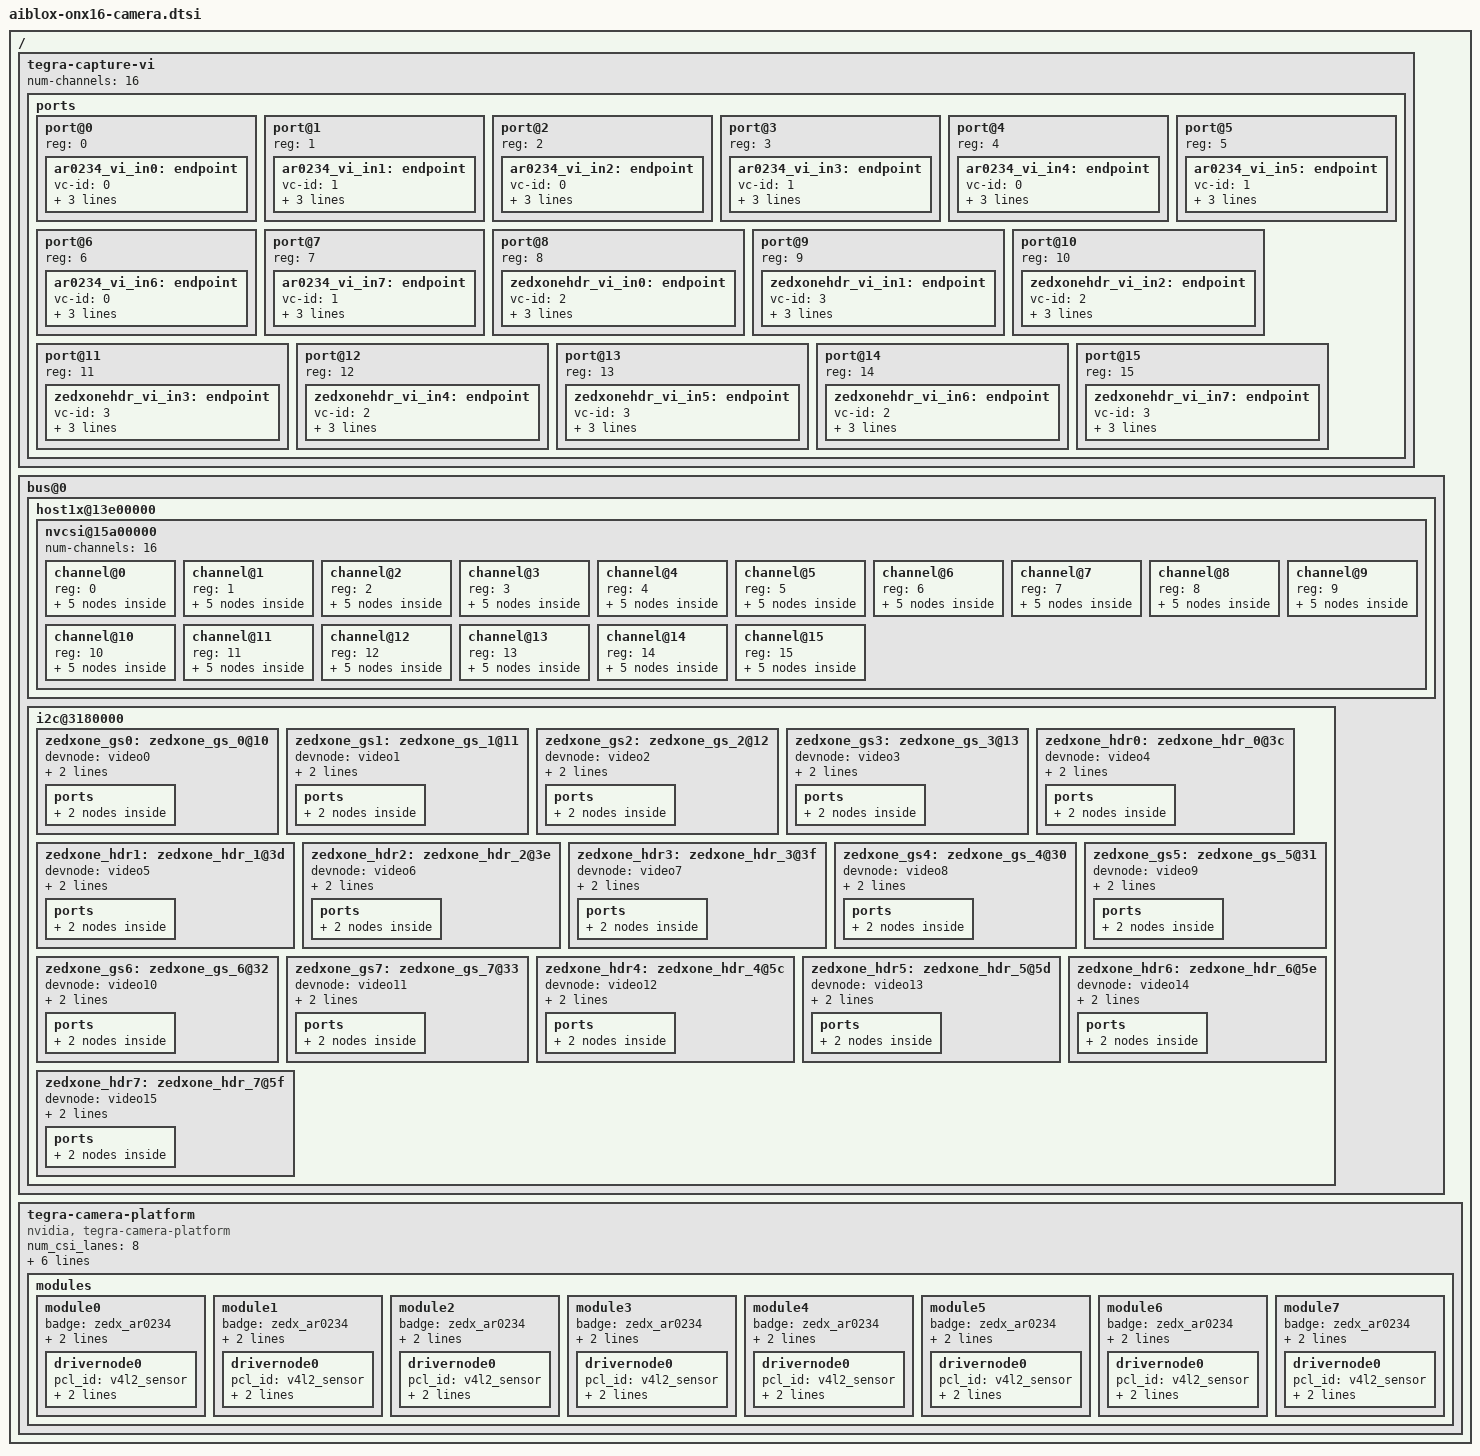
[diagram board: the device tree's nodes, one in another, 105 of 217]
// SPDX-License-Identifier: GPL-2.0-only
// SPDX-FileCopyrightText: Copyright (c) 2023-2024, NVIDIA CORPORATION & AFFILIATES. All rights reserved.

#include "Utils/isx031-sl-modes.dtsi"
#include "Utils/ar0234-sl-modes.dtsi"
#include "Utils/imx678-sl-modes.dtsi"

#define NUM_LANES 2

/ {
	fragment-camera-zedx-aiblox@0 {
		target-path = "/";
		__overlay__ {
			tegra-capture-vi {
				num-channels = <16>;
				ports {
					#address-cells = <1>;
					#size-cells = <0>;
					port@0 {
						reg = <0>;
						status = "okay";
						ar0234_vi_in0: endpoint {
							status = "okay";
							vc-id = <0>;
							port-index = <0>;
							bus-width = <NUM_LANES>;
							remote-endpoint = <&ar0234_csi_out0>;
						};
					};
					port@1 {
						reg = <1>;
						status = "okay";
						ar0234_vi_in1: endpoint {
							status = "okay";
							vc-id = <1>;
							port-index = <0>;
							bus-width = <NUM_LANES>;
							remote-endpoint = <&ar0234_csi_out1>;
						};
					};
					port@2 {
						reg = <2>;
						status = "okay";
						ar0234_vi_in2: endpoint {
							status = "okay";
							vc-id = <0>;
							port-index = <1>;
							bus-width = <NUM_LANES>;
							remote-endpoint = <&ar0234_csi_out2>;
						};
					};
					port@3 {
						reg = <3>;
						status = "okay";
						ar0234_vi_in3: endpoint {
							status = "okay";
							vc-id = <1>;
							port-index = <1>;
							bus-width = <NUM_LANES>;
							remote-endpoint = <&ar0234_csi_out3>;
						};
					};
					port@4 {
						reg = <4>;
						status = "okay";
						ar0234_vi_in4: endpoint {
							status = "okay";
							vc-id = <0>;
							port-index = <2>;
							bus-width = <NUM_LANES>;
							remote-endpoint = <&ar0234_csi_out4>;
						};
					};
					port@5 {
						reg = <5>;
						status = "okay";
						ar0234_vi_in5: endpoint {
							status = "okay";
							vc-id = <1>;
							port-index = <2>;
							bus-width = <NUM_LANES>;
							remote-endpoint = <&ar0234_csi_out5>;
						};
					};
					port@6 {
						reg = <6>;
						status = "okay";
						ar0234_vi_in6: endpoint {
							status = "okay";
							vc-id = <0>;
							port-index = <3>;
							bus-width = <NUM_LANES>;
							remote-endpoint = <&ar0234_csi_out6>;
						};
					};
					port@7 {
						reg = <7>;
						status = "okay";
						ar0234_vi_in7: endpoint {
							status = "okay";
							vc-id = <1>;
							port-index = <3>;
							bus-width = <NUM_LANES>;
							remote-endpoint = <&ar0234_csi_out7>;
						};
					};
					
					port@8 {
						reg = <8>;
						status = "okay";
						zedxonehdr_vi_in0: endpoint {
							status = "okay";
							vc-id = <2>;
							port-index = <0>;
							bus-width = <NUM_LANES>;
							remote-endpoint = <&zedxonehdr_csi_out0>;
						};
					};
					port@9 {
						reg = <9>;
						status = "okay";
						zedxonehdr_vi_in1: endpoint {
							status = "okay";
							vc-id = <3>;
							port-index = <0>;
							bus-width = <NUM_LANES>;
							remote-endpoint = <&zedxonehdr_csi_out1>;
						};
					};
					port@10 {
						reg = <10>;
						status = "okay";
						zedxonehdr_vi_in2: endpoint {
							status = "okay";
							vc-id = <2>;
							port-index = <1>;
							bus-width = <NUM_LANES>;
							remote-endpoint = <&zedxonehdr_csi_out2>;
						};
					};
					port@11 {
						reg = <11>;
						status = "okay";
						zedxonehdr_vi_in3: endpoint {
							status = "okay";
							vc-id = <3>;
							port-index = <1>;
							bus-width = <NUM_LANES>;
							remote-endpoint = <&zedxonehdr_csi_out3>;
						};
					};
					port@12 {
						reg = <12>;
						status = "okay";
						zedxonehdr_vi_in4: endpoint {
							status = "okay";
							vc-id = <2>;
							port-index = <2>;
							bus-width = <NUM_LANES>;
							remote-endpoint = <&zedxonehdr_csi_out4>;
						};
					};
					port@13 {
						reg = <13>;
						status = "okay";
						zedxonehdr_vi_in5: endpoint {
							status = "okay";
							vc-id = <3>;
							port-index = <2>;
							bus-width = <NUM_LANES>;
							remote-endpoint = <&zedxonehdr_csi_out5>;
						};
					};
					port@14 {
						reg = <14>;
						status = "okay";
						zedxonehdr_vi_in6: endpoint {
							status = "okay";
							vc-id = <2>;
							port-index = <3>;
							bus-width = <NUM_LANES>;
							remote-endpoint = <&zedxonehdr_csi_out6>;
						};
					};
					port@15 {
						reg = <15>;
						status = "okay";
						zedxonehdr_vi_in7: endpoint {
							status = "okay";
							vc-id = <3>;
							port-index = <3>;
							bus-width = <NUM_LANES>;
							remote-endpoint = <&zedxonehdr_csi_out7>;
						};
					};
				};
			};
			bus@0 {
				host1x@13e00000 {
					nvcsi@15a00000 {
						num-channels = <16>;
						#address-cells = <1>;
						#size-cells = <0>;
						channel@0 {
							reg = <0>;
							status = "okay";
							ports {
								#address-cells = <1>;
								#size-cells = <0>;
								port@0 {
									reg = <0>;
									status = "okay";
									ar0234_csi_in0: endpoint@0 {
										status = "okay";
										port-index = <0>;
										bus-width = <NUM_LANES>;
										remote-endpoint = <&ar0234_ar0234_out0>;
									};
								};
								port@1 {
									reg = <1>;
									status = "okay";
									ar0234_csi_out0: endpoint@1 {
										status = "okay";
										remote-endpoint = <&ar0234_vi_in0>;
									};
								};
							};
						};
						channel@1 {
							reg = <1>;
							status = "okay";
							ports {
								#address-cells = <1>;
								#size-cells = <0>;
								port@0 {
									reg = <0>;
									status = "okay";
									ar0234_csi_in1: endpoint@2 {
										status = "okay";
										port-index = <0>;
										bus-width = <NUM_LANES>;
										remote-endpoint = <&ar0234_ar0234_out1>;
									};
								};
								port@1 {
									reg = <1>;
									status = "okay";
									ar0234_csi_out1: endpoint@3 {
										status = "okay";
										remote-endpoint = <&ar0234_vi_in1>;
									};
								};
							};
						};
						channel@2 {
							reg = <2>;
							status = "okay";
							ports {
								#address-cells = <1>;
								#size-cells = <0>;
								port@0 {
									reg = <0>;
									status = "okay";
									ar0234_csi_in2: endpoint@4 {
										status = "okay";
										port-index = <1>;
										bus-width = <NUM_LANES>;
										remote-endpoint = <&ar0234_ar0234_out2>;
									};
								};
								port@1 {
									reg = <1>;
									status = "okay";
									ar0234_csi_out2: endpoint@5 {
										status = "okay";
										remote-endpoint = <&ar0234_vi_in2>;
									};
								};
							};
						};
						channel@3 {
							reg = <3>;
							status = "okay";
							ports {
								#address-cells = <1>;
								#size-cells = <0>;
								port@0 {
									reg = <0>;
									status = "okay";
									ar0234_csi_in3: endpoint@6 {
										status = "okay";
										port-index = <1>;
										bus-width = <NUM_LANES>;
										remote-endpoint = <&ar0234_ar0234_out3>;
									};
								};
								port@1 {
									reg = <1>;
									status = "okay";
									ar0234_csi_out3: endpoint@7 {
										status = "okay";
										remote-endpoint = <&ar0234_vi_in3>;
									};
								};
							};
						};
						channel@4 {
							reg = <4>;
							status = "okay";
							ports {
								#address-cells = <1>;
								#size-cells = <0>;
								port@0 {
									reg = <0>;
									status = "okay";
									ar0234_csi_in4: endpoint@8 {
										status = "okay";
										port-index = <2>;
										bus-width = <NUM_LANES>;
										remote-endpoint = <&ar0234_ar0234_out4>;
									};
								};
								port@1 {
									reg = <1>;
									status = "okay";
									ar0234_csi_out4: endpoint@9 {
										status = "okay";
										remote-endpoint = <&ar0234_vi_in4>;
									};
								};
							};
						};
						channel@5 {
							reg = <5>;
							status = "okay";
							ports {
								#address-cells = <1>;
								#size-cells = <0>;
								port@0 {
									reg = <0>;
									status = "okay";
									ar0234_csi_in5: endpoint@10 {
										status = "okay";
										port-index = <2>;
										bus-width = <NUM_LANES>;
										remote-endpoint = <&ar0234_ar0234_out5>;
									};
								};
								port@1 {
									reg = <1>;
									status = "okay";
									ar0234_csi_out5: endpoint@11 {
										status = "okay";
										remote-endpoint = <&ar0234_vi_in5>;
									};
								};
							};
						};
						channel@6 {
							reg = <6>;
							status = "okay";
							ports {
								#address-cells = <1>;
								#size-cells = <0>;
								port@0 {
									reg = <0>;
									status = "okay";
									ar0234_csi_in6: endpoint@12 {
										status = "okay";
										port-index = <3>;
										bus-width = <NUM_LANES>;
										remote-endpoint = <&ar0234_ar0234_out6>;
									};
								};
								port@1 {
									reg = <1>;
									status = "okay";
									ar0234_csi_out6: endpoint@13 {
										status = "okay";
										remote-endpoint = <&ar0234_vi_in6>;
									};
								};
							};
						};
						channel@7 {
							reg = <7>;
							status = "okay";
							ports {
								#address-cells = <1>;
								#size-cells = <0>;
								port@0 {
									reg = <0>;
									status = "okay";
									ar0234_csi_in7: endpoint@14 {
										status = "okay";
										port-index = <3>;
										bus-width = <NUM_LANES>;
										remote-endpoint = <&ar0234_ar0234_out7>;
									};
								};
								port@1 {
									reg = <1>;
									status = "okay";
									ar0234_csi_out7: endpoint@15 {
										status = "okay";
										remote-endpoint = <&ar0234_vi_in7>;
									};
								};
							};
						};
						
						channel@8 {
							reg = <8>;
							status = "okay";
							ports {
								#address-cells = <1>;
								#size-cells = <0>;
								port@0 {
									reg = <0>;
									status = "okay";
									zedxonehdr_csi_in0: endpoint@16 {
										status = "okay";
										port-index = <0>;
										bus-width = <NUM_LANES>;
										remote-endpoint = <&zedxonehdr_isx031_out0>;
									};
								};
								port@1 {
									reg = <1>;
									status = "okay";
									zedxonehdr_csi_out0: endpoint@17 {
										status = "okay";
										remote-endpoint = <&zedxonehdr_vi_in0>;
									};
								};
							};
						};
						channel@9 {
							reg = <9>;
							status = "okay";
							ports {
								#address-cells = <1>;
								#size-cells = <0>;
								port@0 {
									reg = <0>;
									status = "okay";
									zedxonehdr_csi_in1: endpoint@18 {
										status = "okay";
										port-index = <0>;
										bus-width = <NUM_LANES>;
										remote-endpoint = <&zedxonehdr_isx031_out1>;
									};
								};
								port@1 {
									reg = <1>;
									status = "okay";
									zedxonehdr_csi_out1: endpoint@19 {
										status = "okay";
										remote-endpoint = <&zedxonehdr_vi_in1>;
									};
								};
							};
						};
						channel@10 {
							reg = <10>;
							status = "okay";
							ports {
								#address-cells = <1>;
								#size-cells = <0>;
								port@0 {
									reg = <0>;
									status = "okay";
									zedxonehdr_csi_in2: endpoint@20 {
										status = "okay";
										port-index = <1>;
										bus-width = <NUM_LANES>;
										remote-endpoint = <&zedxonehdr_isx031_out2>;
									};
								};
								port@1 {
									reg = <1>;
									status = "okay";
									zedxonehdr_csi_out2: endpoint@21 {
										status = "okay";
										remote-endpoint = <&zedxonehdr_vi_in2>;
									};
								};
							};
						};
						channel@11 {
							reg = <11>;
							status = "okay";
							ports {
								#address-cells = <1>;
								#size-cells = <0>;
								port@0 {
									reg = <0>;
									status = "okay";
									zedxonehdr_csi_in3: endpoint@22 {
										status = "okay";
										port-index = <1>;
										bus-width = <NUM_LANES>;
										remote-endpoint = <&zedxonehdr_isx031_out3>;
									};
								};
								port@1 {
									reg = <1>;
									status = "okay";
									zedxonehdr_csi_out3: endpoint@23 {
										status = "okay";
										remote-endpoint = <&zedxonehdr_vi_in3>;
									};
								};
							};
						};
						channel@12 {
							reg = <12>;
							status = "okay";
							ports {
								#address-cells = <1>;
								#size-cells = <0>;
								port@0 {
									reg = <0>;
									status = "okay";
									zedxonehdr_csi_in4: endpoint@24 {
										status = "okay";
										port-index = <2>;
										bus-width = <NUM_LANES>;
										remote-endpoint = <&zedxonehdr_isx031_out4>;
									};
								};
								port@1 {
									reg = <1>;
									status = "okay";
									zedxonehdr_csi_out4: endpoint@25 {
										status = "okay";
										remote-endpoint = <&zedxonehdr_vi_in4>;
									};
								};
							};
						};
						channel@13 {
							reg = <13>;
							status = "okay";
							ports {
								#address-cells = <1>;
								#size-cells = <0>;
								port@0 {
									reg = <0>;
									status = "okay";
									zedxonehdr_csi_in5: endpoint@26 {
										status = "okay";
										port-index = <2>;
										bus-width = <NUM_LANES>;
										remote-endpoint = <&zedxonehdr_isx031_out5>;
									};
								};
								port@1 {
									reg = <1>;
									status = "okay";
									zedxonehdr_csi_out5: endpoint@27 {
										status = "okay";
										remote-endpoint = <&zedxonehdr_vi_in5>;
									};
								};
							};
						};
						channel@14 {
							reg = <14>;
							status = "okay";
							ports {
								#address-cells = <1>;
								#size-cells = <0>;
								port@0 {
									reg = <0>;
									status = "okay";
									zedxonehdr_csi_in6: endpoint@28 {
										status = "okay";
										port-index = <3>;
										bus-width = <NUM_LANES>;
										remote-endpoint = <&zedxonehdr_isx031_out6>;
									};
								};
								port@1 {
									reg = <1>;
									status = "okay";
									zedxonehdr_csi_out6: endpoint@29 {
										status = "okay";
										remote-endpoint = <&zedxonehdr_vi_in6>;
									};
								};
							};
						};
						channel@15 {
							reg = <15>;
							status = "okay";
							ports {
								#address-cells = <1>;
								#size-cells = <0>;
								port@0 {
									reg = <0>;
									status = "okay";
									zedxonehdr_csi_in7: endpoint@30 {
										status = "okay";
										port-index = <3>;
										bus-width = <NUM_LANES>;
										remote-endpoint = <&zedxonehdr_isx031_out7>;
									};
								};
								port@1 {
									reg = <1>;
									status = "okay";
									zedxonehdr_csi_out7: endpoint@31 {
										status = "okay";
										remote-endpoint = <&zedxonehdr_vi_in7>;
									};
								};
							};
						};
					};
				};
				
				i2c@3180000{
					/* Channel A */
					/* ZEDX One GS 0 camera sensor */
					zedxone_gs0: zedxone_gs_0@10 {
						
						devnode = "video0";
						
						sync_sensor = "ZEDXONE_CAM0";
						sync_sensor_index = <1>;
						
						AR0234_MODES("0", "serial_a", "6")
						
						ports {
							#address-cells = <1>;
							#size-cells = <0>;
							port@0 {
								reg = <0>;
								ar0234_ar0234_out0: endpoint {
									vc-id = <0>;
									port-index = <0>;
									opt-csi-port = "e";
									bus-width = <NUM_LANES>;
									i2c-cc = <1>;
									remote-endpoint = <&ar0234_csi_in0>;
								};
							};
						};
					};
					
					/* ZEDX One GS 1 camera sensor */
					zedxone_gs1: zedxone_gs_1@11 {
						
						devnode = "video1";
						
						sync_sensor = "ZEDXONE_CAM2";
						sync_sensor_index = <1>;
						
						AR0234_MODES("1", "serial_a", "6")
						
						ports {
							#address-cells = <1>;
							#size-cells = <0>;
							port@0 {
								reg = <0>;
								ar0234_ar0234_out1: endpoint {
									vc-id = <1>;
									port-index = <0>;
									opt-csi-port = "e";
									bus-width = <NUM_LANES>;
									i2c-cc = <1>;
									remote-endpoint = <&ar0234_csi_in1>;
								};
							};
						};
					};
					
					/* ZEDX One GS 2 camera sensor */
					zedxone_gs2: zedxone_gs_2@12 {
						
						devnode = "video2";
						
						sync_sensor = "ZEDXONE_CAM1";
						sync_sensor_index = <1>;
						
						AR0234_MODES("0", "serial_b", "6")
						
						ports {
							#address-cells = <1>;
							#size-cells = <0>;
							port@0 {
								reg = <0>;
								ar0234_ar0234_out2: endpoint {
									vc-id = <0>;
									port-index = <1>;
									opt-csi-port = "f";
									bus-width = <NUM_LANES>;
									i2c-cc = <1>;
									remote-endpoint = <&ar0234_csi_in2>;
								};
							};
						};
					};
					
					/* ZEDX One GS 3 camera sensor */
					zedxone_gs3: zedxone_gs_3@13 {
						
						devnode = "video3";
						
						sync_sensor = "ZEDXONE_CAM3";
						sync_sensor_index = <1>;
						
						AR0234_MODES("1", "serial_b", "6")
						
						ports {
							#address-cells = <1>;
							#size-cells = <0>;
							port@0 {
								reg = <0>;
								ar0234_ar0234_out3: endpoint {
									vc-id = <1>;
									port-index = <1>;
									opt-csi-port = "f";
									bus-width = <NUM_LANES>;
									i2c-cc = <1>;
									remote-endpoint = <&ar0234_csi_in3>;
								};
							};
						};
					};
					
					
					zedxone_hdr0: zedxone_hdr_0@3c {
						
						devnode = "video4";
						
						sync_sensor = "ZEDXONE_CAM6";
						sync_sensor_index = <1>;
						
						ISX031_MODES("2", "serial_a", "6")
						
						ports {
							#address-cells = <1>;
							#size-cells = <0>;
							port@0 {
								reg = <0>;
								zedxonehdr_isx031_out0: endpoint {
									vc-id = <2>;
									port-index = <0>;
									opt-csi-port = "e";
									bus-width = <NUM_LANES>;
									i2c-cc = <1>;
									remote-endpoint = <&zedxonehdr_csi_in0>;
								};
							};
						};
					};
					
					zedxone_hdr1: zedxone_hdr_1@3d {
						
						devnode = "video5";
						
						sync_sensor = "ZEDXONE_CAM8";
						sync_sensor_index = <1>;
						
						ISX031_MODES("3", "serial_a", "6")
						
						ports {
							#address-cells = <1>;
							#size-cells = <0>;
							port@0 {
								reg = <0>;
								zedxonehdr_isx031_out1: endpoint {
									vc-id = <3>;
									port-index = <0>;
									opt-csi-port = "e";
									bus-width = <NUM_LANES>;
									i2c-cc = <1>;
									remote-endpoint = <&zedxonehdr_csi_in1>;
								};
							};
						};
					};
					
					zedxone_hdr2: zedxone_hdr_2@3e {
						
						devnode = "video6";
						
						sync_sensor = "ZEDXONE_CAM7";
						sync_sensor_index = <1>;
						
						ISX031_MODES("2", "serial_b", "6")
						
						ports {
							#address-cells = <1>;
							#size-cells = <0>;
							port@0 {
								reg = <0>;
								zedxonehdr_isx031_out2: endpoint {
									vc-id = <2>;
									port-index = <1>;
									opt-csi-port = "f";
									bus-width = <NUM_LANES>;
									i2c-cc = <1>;
									remote-endpoint = <&zedxonehdr_csi_in2>;
								};
							};
						};
					};
					
					zedxone_hdr3: zedxone_hdr_3@3f {
						
						devnode = "video7";
						
						sync_sensor = "ZEDXONE_CAM9";
						sync_sensor_index = <1>;
						
						ISX031_MODES("3", "serial_b", "6")
						
						ports {
							#address-cells = <1>;
							#size-cells = <0>;
							port@0 {
								reg = <0>;
								zedxonehdr_isx031_out3: endpoint {
									vc-id = <3>;
									port-index = <1>;
									opt-csi-port = "f";
									bus-width = <NUM_LANES>;
									i2c-cc = <1>;
									remote-endpoint = <&zedxonehdr_csi_in3>;
								};
							};
						};
					};
					
					/* Channel B */
					
					
					/* ZEDX One GS 4 camera sensor */
					zedxone_gs4: zedxone_gs_4@30 {
						
						devnode = "video8";
						
						sync_sensor = "ZEDXONE_CAM10";
						sync_sensor_index = <1>;
						
						AR0234_MODES("0", "serial_c", "0")
						
						ports {
							#address-cells = <1>;
							#size-cells = <0>;
							port@0 {
								reg = <0>;
								ar0234_ar0234_out4: endpoint {
									vc-id = <0>;
									port-index = <2>;
									opt-csi-port = "e";
									bus-width = <NUM_LANES>;
									i2c-cc = <1>;
									remote-endpoint = <&ar0234_csi_in4>;
								};
							};
						};
					};
					
					/* ZEDX One GS 5 camera sensor */
					zedxone_gs5: zedxone_gs_5@31 {
						
						devnode = "video9";
						
						sync_sensor = "ZEDXONE_CAM12";
						sync_sensor_index = <1>;
						
						AR0234_MODES("1", "serial_c", "0")
						
						ports {
							#address-cells = <1>;
							#size-cells = <0>;
							port@0 {
								reg = <0>;
								ar0234_ar0234_out5: endpoint {
									vc-id = <1>;
									port-index = <2>;
									opt-csi-port = "e";
									bus-width = <NUM_LANES>;
									i2c-cc = <1>;
									remote-endpoint = <&ar0234_csi_in5>;
								};
							};
						};
					};
					
					/* ZEDX One GS 6 camera sensor */
					zedxone_gs6: zedxone_gs_6@32 {
						
						devnode = "video10";
						
						sync_sensor = "ZEDXONE_CAM11";
						sync_sensor_index = <1>;
						
						AR0234_MODES("0", "serial_d", "0")
						
						ports {
							#address-cells = <1>;
							#size-cells = <0>;
							port@0 {
								reg = <0>;
								ar0234_ar0234_out6: endpoint {
									vc-id = <0>;
									port-index = <3>;
									opt-csi-port = "f";
									bus-width = <NUM_LANES>;
									i2c-cc = <1>;
									remote-endpoint = <&ar0234_csi_in6>;
								};
							};
						};
					};
					
					/* ZEDX One GS 7 camera sensor */
					zedxone_gs7: zedxone_gs_7@33 {
						
						devnode = "video11";
						
						sync_sensor = "ZEDXONE_CAM13";
						sync_sensor_index = <1>;
						
						AR0234_MODES("1", "serial_d", "0")
						
						ports {
							#address-cells = <1>;
							#size-cells = <0>;
							port@0 {
								reg = <0>;
								ar0234_ar0234_out7: endpoint {
									vc-id = <1>;
									port-index = <3>;
									opt-csi-port = "f";
									bus-width = <NUM_LANES>;
									i2c-cc = <1>;
									remote-endpoint = <&ar0234_csi_in7>;
								};
							};
						};
					};
					
					zedxone_hdr4: zedxone_hdr_4@5c {
						
						devnode = "video12";
						
						sync_sensor = "ZEDXONE_CAM16";
						sync_sensor_index = <1>;
						
						ISX031_MODES("2", "serial_c", "0")
						
						ports {
							#address-cells = <1>;
							#size-cells = <0>;
							port@0 {
								reg = <0>;
								zedxonehdr_isx031_out4: endpoint {
									vc-id = <0>;
									port-index = <2>;
									opt-csi-port = "e";
									bus-width = <NUM_LANES>;
									i2c-cc = <1>;
									remote-endpoint = <&zedxonehdr_csi_in4>;
								};
							};
						};
					};
					
					zedxone_hdr5: zedxone_hdr_5@5d {
						
						devnode = "video13";
						
						sync_sensor = "ZEDXONE_CAM18";
						sync_sensor_index = <1>;
						
						ISX031_MODES("3", "serial_c", "0")
						
						ports {
							#address-cells = <1>;
							#size-cells = <0>;
							port@0 {
								reg = <0>;
								zedxonehdr_isx031_out5: endpoint {
									vc-id = <3>;
									port-index = <2>;
									opt-csi-port = "e";
									bus-width = <NUM_LANES>;
									i2c-cc = <1>;
									remote-endpoint = <&zedxonehdr_csi_in5>;
								};
							};
						};
					};
					
					zedxone_hdr6: zedxone_hdr_6@5e {
						
						devnode = "video14";
						
						sync_sensor = "ZEDXONE_CAM17";
						sync_sensor_index = <1>;
						
						ISX031_MODES("2", "serial_d", "0")
						
						ports {
							#address-cells = <1>;
							#size-cells = <0>;
							port@0 {
								reg = <0>;
								zedxonehdr_isx031_out6: endpoint {
									vc-id = <2>;
									port-index = <3>;
									opt-csi-port = "f";
									bus-width = <NUM_LANES>;
									i2c-cc = <1>;
									remote-endpoint = <&zedxonehdr_csi_in6>;
								};
							};
						};
					};
					
					zedxone_hdr7: zedxone_hdr_7@5f {
						
						devnode = "video15";
						
						sync_sensor = "ZEDXONE_CAM19";
						sync_sensor_index = <1>;
						
						ISX031_MODES("3", "serial_d", "0")
						
						ports {
							#address-cells = <1>;
							#size-cells = <0>;
							port@0 {
								reg = <0>;
								zedxonehdr_isx031_out7: endpoint {
									vc-id = <3>;
									port-index = <3>;
									opt-csi-port = "f";
									bus-width = <NUM_LANES>;
									i2c-cc = <1>;
									remote-endpoint = <&zedxonehdr_csi_in7>;
								};
							};
						};
					};
				};
			};
			
			tegra-camera-platform {
				compatible = "nvidia, tegra-camera-platform";
				/**
				* Physical settings to calculate max ISO BW
				*
				* num_csi_lanes = <>;
				* Total number of CSI lanes when all cameras are active
				*
				* max_lane_speed = <>;
				* Max lane speed in Kbit/s
				*
				* min_bits_per_pixel = <>;
				* Min bits per pixel
				*
				* vi_peak_byte_per_pixel = <>;
				* Max byte per pixel for the VI ISO case
				*
				* vi_bw_margin_pct = <>;
				* Vi bandwidth margin in percentage
				*
				* max_pixel_rate = <>;
				* Max pixel rate in Kpixel/s for the ISP ISO case
				*
				* isp_peak_byte_per_pixel = <>;
				* Max byte per pixel for the ISP ISO case
				*
				* isp_bw_margin_pct = <>;
				* Isp bandwidth margin in percentage
				*/
				
				num_csi_lanes = <8>;
				max_lane_speed = <2000000>;
				min_bits_per_pixel = <8>;
				vi_peak_byte_per_pixel = <2>;
				vi_bw_margin_pct = <25>;
				isp_peak_byte_per_pixel = <5>;
				isp_bw_margin_pct = <25>;
				
				/**
				* The general guideline for naming badge_info contains 3 parts, and is as follows,
				* The first part is the camera_board_id for the module; if the module is in a FFD
				* platform, then use the platform name for this part.
				* The second part contains the position of the module, ex. "rear" or "front".
				* The third part contains the last 6 characters of a part number which is found
				* in the module's specsheet from the vender.
				*/
				modules {
					module0 {
						badge = "zedx_ar0234";
						position = "front";
						orientation = "1";
						status = "okay";
						drivernode0 {
							status = "okay";
							/* Declare PCL support driver (classically known as guid)  */
							pcl_id = "v4l2_sensor";
							/* Declare the device-tree hierarchy to driver instance */
							sysfs-device-tree = "/sys/firmware/devicetree/base/bus@0/i2c@3180000/zedxone_gs_0@10";
						};
					};
					module1 {
						badge = "zedx_ar0234";
						position = "front";
						orientation = "1";
						status = "okay";
						drivernode0 {
							status = "okay";
							/* Declare PCL support driver (classically known as guid)  */
							pcl_id = "v4l2_sensor";
							/* Declare the device-tree hierarchy to driver instance */
							sysfs-device-tree = "/sys/firmware/devicetree/base/bus@0/i2c@3180000/zedxone_gs_1@11";
						};
					};
					module2 {
						badge = "zedx_ar0234";
						position = "front";
						orientation = "1";
						status = "okay";
						drivernode0 {
							status = "okay";
							/* Declare PCL support driver (classically known as guid)  */
							pcl_id = "v4l2_sensor";
							/* Declare the device-tree hierarchy to driver instance */
							sysfs-device-tree = "/sys/firmware/devicetree/base/bus@0/i2c@3180000/zedxone_gs_2@12";
						};
					};
					module3 {
						badge = "zedx_ar0234";
						position = "front";
						orientation = "1";
						status = "okay";
						drivernode0 {
							status = "okay";
							/* Declare PCL support driver (classically known as guid)  */
							pcl_id = "v4l2_sensor";
							/* Declare the device-tree hierarchy to driver instance */
							sysfs-device-tree = "/sys/firmware/devicetree/base/bus@0/i2c@3180000/zedxone_gs_3@13";
						};
					};
					module4 {
						badge = "zedx_ar0234";
						position = "front";
						orientation = "1";
						status = "okay";
						drivernode0 {
							status = "okay";
							/* Declare PCL support driver (classically known as guid)  */
							pcl_id = "v4l2_sensor";
							/* Declare the device-tree hierarchy to driver instance */
							sysfs-device-tree = "/sys/firmware/devicetree/base/bus@0/i2c@3180000/zedxone_gs_4@30";
						};
					};
					module5 {
						badge = "zedx_ar0234";
						position = "front";
						orientation = "1";
						status = "okay";
						drivernode0 {
							status = "okay";
							/* Declare PCL support driver (classically known as guid)  */
							pcl_id = "v4l2_sensor";
							/* Declare the device-tree hierarchy to driver instance */
							sysfs-device-tree = "/sys/firmware/devicetree/base/bus@0/i2c@3180000/zedxone_gs_5@31";
						};
					};
					module6 {
						badge = "zedx_ar0234";
						position = "front";
						orientation = "1";
						status = "okay";
						drivernode0 {
							status = "okay";
							/* Declare PCL support driver (classically known as guid)  */
							pcl_id = "v4l2_sensor";
							/* Declare the device-tree hierarchy to driver instance */
							sysfs-device-tree = "/sys/firmware/devicetree/base/bus@0/i2c@3180000/zedxone_gs_6@32";
						};
					};
					module7 {
						badge = "zedx_ar0234";
						position = "front";
						orientation = "1";
						status = "okay";
						drivernode0 {
							status = "okay";
							/* Declare PCL support driver (classically known as guid)  */
							pcl_id = "v4l2_sensor";
							/* Declare the device-tree hierarchy to driver instance */
							sysfs-device-tree = "/sys/firmware/devicetree/base/bus@0/i2c@3180000/zedxone_gs_7@33";
						};
					};
				};
			};
		};
	};
};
